VERSION ""

NS_ :

BS_:

BU_: Device Host

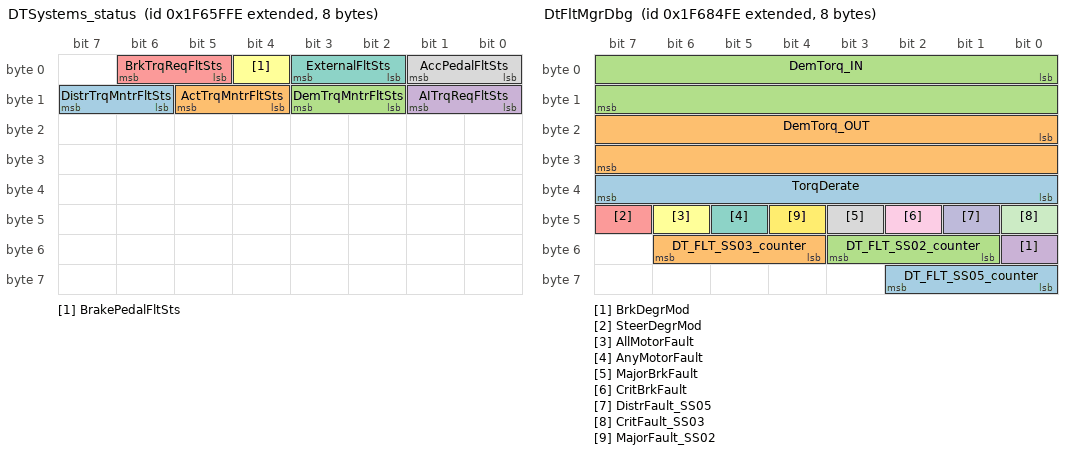
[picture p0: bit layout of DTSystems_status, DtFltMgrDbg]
BO_ 2180407294 DTSystems_status: 8 Vector__XXX
 SG_ DistrTrqMntrFltSts : 14|2@1+ (1,0) [0|3] "" Vector__XXX
 SG_ ActTrqMntrFltSts : 12|2@1+ (1,0) [0|3] "" Vector__XXX
 SG_ DemTrqMntrFltSts : 10|2@1+ (1,0) [0|3] "" Vector__XXX
 SG_ AITrqReqFltSts : 8|2@1+ (1,0) [0|3] "" Vector__XXX
 SG_ BrkTrqReqFltSts : 5|2@1+ (1,0) [0|3] "" Vector__XXX
 SG_ BrakePedalFltSts : 4|1@1+ (1,0) [0|1] "" Vector__XXX
 SG_ ExternalFltSts : 2|2@1+ (1,0) [0|3] "" Vector__XXX
 SG_ AccPedalFltSts : 0|2@1+ (1,0) [0|3] "" Vector__XXX

BO_ 2180416766 DtFltMgrDbg: 8 Vector__XXX
 SG_ DT_FLT_SS05_counter : 56|3@1+ (1,0) [0|7] "" Vector__XXX
 SG_ DT_FLT_SS03_counter : 52|3@1+ (1,0) [0|7] "" Vector__XXX
 SG_ DT_FLT_SS02_counter : 49|3@1+ (1,0) [0|7] "" Vector__XXX
 SG_ BrkDegrMod : 48|1@1+ (1,0) [0|1] "" Vector__XXX
 SG_ SteerDegrMod : 47|1@1+ (1,0) [0|1] "" Vector__XXX
 SG_ AllMotorFault : 46|1@1+ (1,0) [0|1] "" Vector__XXX
 SG_ AnyMotorFault : 45|1@1+ (1,0) [0|1] "" Vector__XXX
 SG_ MajorBrkFault : 43|1@1+ (1,0) [0|1] "" Vector__XXX
 SG_ CritBrkFault : 42|1@1+ (1,0) [0|1] "" Vector__XXX
 SG_ DistrFault_SS05 : 41|1@1+ (1,0) [0|1] "" Vector__XXX
 SG_ CritFault_SS03 : 40|1@1+ (1,0) [0|1] "" Vector__XXX
 SG_ MajorFault_SS02 : 44|1@1+ (1,0) [0|1] "" Vector__XXX
 SG_ TorqDerate : 32|8@1+ (0.004,0) [0|1.02] "" Vector__XXX
 SG_ DemTorq_OUT : 16|16@1+ (1,-32768) [-32768|32767] "" Vector__XXX
 SG_ DemTorq_IN : 0|16@1+ (1,-32768) [-32768|32767] "" Vector__XXX

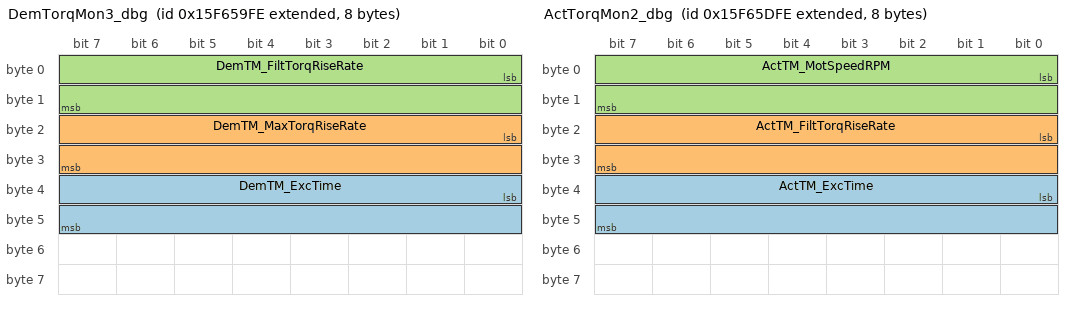
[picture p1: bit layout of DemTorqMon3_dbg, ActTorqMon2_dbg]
BO_ 2515950078 DemTorqMon3_dbg: 8 Vector__XXX
 SG_ DemTM_ExcTime : 32|16@1+ (1,0) [0|65535] "" Vector__XXX
 SG_ DemTM_MaxTorqRiseRate : 16|16@1+ (1,-32267) [-32267|33268] "" Vector__XXX
 SG_ DemTM_FiltTorqRiseRate : 0|16@1+ (1,-32267) [-32267|33268] "" Vector__XXX

BO_ 2515950334 DemTorqMon2_dbg: 8 Vector__XXX
 SG_ DemTM_UpperTorqLim_tab : 16|16@1+ (1,-32267) [-32267|33268] "" Vector__XXX
 SG_ DemTM_LowerTorqLim_tab : 0|16@1+ (1,-32267) [-32267|33268] "" Vector__XXX

BO_ 2515951102 ActTorqMon2_dbg: 8 Vector__XXX
 SG_ ActTM_ExcTime : 32|16@1+ (1,0) [0|65535] "" Vector__XXX
 SG_ ActTM_FiltTorqRiseRate : 16|16@1+ (1,-32267) [-32267|33268] "" Vector__XXX
 SG_ ActTM_MotSpeedRPM : 0|16@1+ (1,-32267) [-32267|33268] "" Vector__XXX

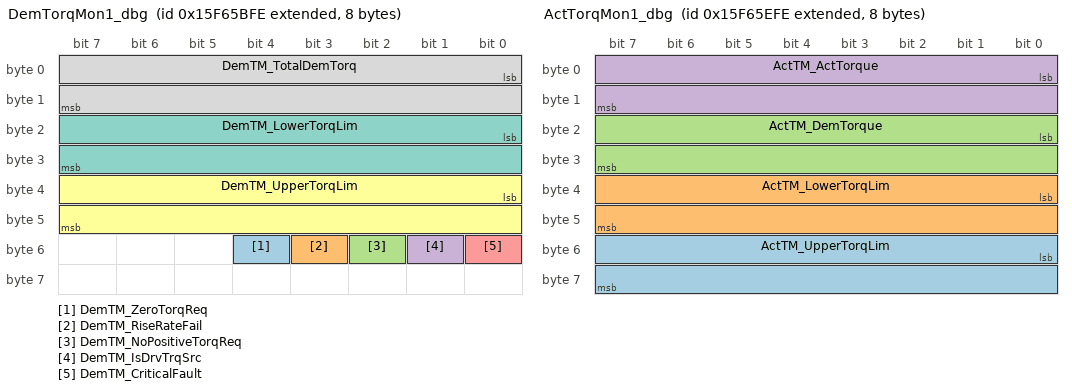
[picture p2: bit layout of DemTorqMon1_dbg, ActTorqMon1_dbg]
BO_ 2515950590 DemTorqMon1_dbg: 8 Vector__XXX
 SG_ DemTM_ZeroTorqReq : 52|1@1+ (1,0) [0|1] "" Vector__XXX
 SG_ DemTM_RiseRateFail : 51|1@1+ (1,0) [0|1] "" Vector__XXX
 SG_ DemTM_NoPositiveTorqReq : 50|1@1+ (1,0) [0|1] "" Vector__XXX
 SG_ DemTM_IsDrvTrqSrc : 49|1@1+ (1,0) [0|1] "" Vector__XXX
 SG_ DemTM_CriticalFault : 48|1@1+ (1,0) [0|1] "" Vector__XXX
 SG_ DemTM_UpperTorqLim : 32|16@1+ (1,-32267) [-32267|33268] "" Vector__XXX
 SG_ DemTM_LowerTorqLim : 16|16@1+ (1,-32267) [-32267|33268] "" Vector__XXX
 SG_ DemTM_TotalDemTorq : 0|16@1+ (1,-32267) [-32267|33268] "" Vector__XXX

BO_ 2515951358 ActTorqMon1_dbg: 8 Vector__XXX
 SG_ ActTM_UpperTorqLim : 48|16@1+ (1,-32267) [-32267|33268] "" Vector__XXX
 SG_ ActTM_LowerTorqLim : 32|16@1+ (1,-32267) [-32267|33268] "" Vector__XXX
 SG_ ActTM_DemTorque : 16|16@1+ (1,-32267) [-32267|33268] "" Vector__XXX
 SG_ ActTM_ActTorque : 0|16@1+ (1,-32267) [-32267|33268] "" Vector__XXX

BO_ 2515950846 BrkTorqMon_dbg: 8 Vector__XXX
 SG_ BrkTM_BrkTorqFault0 : 16|1@1+ (1,0) [0|1] "" Vector__XXX
 SG_ BrkTM_EBSTorqDem : 0|16@1+ (1,-32267) [-32267|33268] "" Vector__XXX

CM_ "Arrival Bus Drivetrain System Database";
CM_ BO_ 2180416766 "Drivetrain Fault Manager Debug";
BA_DEF_  "BusType" STRING ;
BA_DEF_  "DBName" STRING ;
BA_DEF_  "DatabaseVersion" STRING ;
BA_DEF_ BO_  "GenMsgCycleTime" INT 0 3600000;
BA_DEF_ BO_  "Producer" STRING ;
BA_DEF_ BO_  "GenMsgDelayTime" INT 0 1000;
BA_DEF_ BO_  "GenMsgILSupport" ENUM  "No","Yes";
BA_DEF_ BO_  "GenMsgRequestable" INT 0 1;
BA_DEF_ BO_  "GenMsgSendType" ENUM  "cyclic","NotUsed","NotUsed","NotUsed","NotUsed","NotUsed","NotUsed","IfActive","noMsgSendType";
BA_DEF_ SG_  "GenSigEVName" STRING ;
BA_DEF_ SG_  "GenSigILSupport" ENUM  "No","Yes";
BA_DEF_ SG_  "GenSigSendType" ENUM  "Cyclic","OnWrite","OnWriteWithRepetition","OnChange","OnChangeWithRepetition","IfActive","IfActiveWithRepetition","NoSigSendType";
BA_DEF_ SG_  "GenSigStartValue" INT 0 2147483647;
BA_DEF_ BU_  "NmStationAddress" INT 0 255;
BA_DEF_  "ProtocolType" STRING ;
BA_DEF_  "SAE_J1939_21_SpecVersion" STRING ;
BA_DEF_  "SAE_J1939_71_SpecVersion" STRING ;
BA_DEF_  "SAE_J1939_73_SpecVersion" STRING ;
BA_DEF_  "SAE_J1939_75_SpecVersion" STRING ;
BA_DEF_  "SAE_J1939_81_SpecVersion" STRING ;
BA_DEF_  "SAE_J1939_DA_SpecVersion" STRING ;
BA_DEF_ BO_  "SendOnChange" ENUM  "No","Yes";
BA_DEF_ SG_  "SigType" ENUM  "Default","Range","RangeSigned","ASCII","Discrete","Control","ReferencePGN","DTC","StringDelimiter","StringLength","StringLengthControl","MessageCounter","MessageChecksum";
BA_DEF_ BO_  "VFrameFormat" ENUM  "StandardCAN","ExtendedCAN","reserved","J1939PG","reserved","reserved","reserved","reserved","reserved","reserved","reserved","reserved","reserved","reserved","StandardCAN_FD","ExtendedCAN_FD";
BA_DEF_DEF_  "BusType" "";
BA_DEF_DEF_ "Producer" "DTS" ;
BA_DEF_DEF_  "DBName" "";
BA_DEF_DEF_  "DatabaseVersion" "";
BA_DEF_DEF_  "GenMsgCycleTime" 0;
BA_DEF_DEF_  "GenMsgDelayTime" 0;
BA_DEF_DEF_  "GenMsgILSupport" "Yes";
BA_DEF_DEF_  "GenMsgRequestable" 1;
BA_DEF_DEF_  "GenMsgSendType" "noMsgSendType";
BA_DEF_DEF_  "GenSigEVName" "Env@Nodename_@Signame";
BA_DEF_DEF_  "GenSigILSupport" "Yes";
BA_DEF_DEF_  "GenSigSendType" "NoSigSendType";
BA_DEF_DEF_  "GenSigStartValue" 0;
BA_DEF_DEF_  "NmStationAddress" 254;
BA_DEF_DEF_  "ProtocolType" "";
BA_DEF_DEF_  "SAE_J1939_21_SpecVersion" "";
BA_DEF_DEF_  "SAE_J1939_71_SpecVersion" "";
BA_DEF_DEF_  "SAE_J1939_73_SpecVersion" "";
BA_DEF_DEF_  "SAE_J1939_75_SpecVersion" "";
BA_DEF_DEF_  "SAE_J1939_81_SpecVersion" "";
BA_DEF_DEF_  "SAE_J1939_DA_SpecVersion" "";
BA_DEF_DEF_  "SendOnChange" "No";
BA_DEF_DEF_  "SigType" "Default";
BA_DEF_DEF_  "VFrameFormat" "J1939PG";
BA_ "SAE_J1939_DA_SpecVersion" "2015-01";
BA_ "SAE_J1939_81_SpecVersion" "2012-05";
BA_ "SAE_J1939_75_SpecVersion" "2012-05";
BA_ "SAE_J1939_73_SpecVersion" "2012-10";
BA_ "SAE_J1939_71_SpecVersion" "2012-10";
BA_ "SAE_J1939_21_SpecVersion" "2006-10";
BA_ "ProtocolType" "J1939";
BA_ "DatabaseVersion" "1.0";
BA_ "BusType" "CAN";
BA_ "DBName" "DrivetrainSystem";
BA_ "GenMsgCycleTime" BO_ 2180407294 1000;
BA_ "GenMsgDelayTime" BO_ 2180407294 100;
BA_ "GenMsgSendType" BO_ 2180407294 0;
BA_ "SendOnChange" BO_ 2180407294 1;
BA_ "SendOnChange" BO_ 2180416766 1;
BA_ "GenMsgDelayTime" BO_ 2180416766 100;
BA_ "GenMsgCycleTime" BO_ 2180416766 1000;
BA_ "GenMsgSendType" BO_ 2180416766 0;
BA_ "GenMsgCycleTime" BO_ 2515950078 100;
BA_ "GenMsgSendType" BO_ 2515950078 0;
BA_ "GenMsgCycleTime" BO_ 2515950334 100;
BA_ "GenMsgSendType" BO_ 2515950334 0;
BA_ "GenMsgCycleTime" BO_ 2515951102 100;
BA_ "GenMsgSendType" BO_ 2515951102 0;
BA_ "GenMsgSendType" BO_ 2515950590 0;
BA_ "GenMsgCycleTime" BO_ 2515950590 100;
BA_ "GenMsgSendType" BO_ 2515951358 0;
BA_ "GenMsgCycleTime" BO_ 2515951358 100;
BA_ "GenMsgSendType" BO_ 2515950846 0;
BA_ "GenMsgCycleTime" BO_ 2515950846 100;
BA_ "GenSigStartValue" SG_ 2180416766 DemTorq_OUT 32768;
BA_ "GenSigStartValue" SG_ 2180416766 DemTorq_IN 32768;
BA_ "GenSigStartValue" SG_ 2515950078 DemTM_MaxTorqRiseRate 32267;
BA_ "GenSigStartValue" SG_ 2515950078 DemTM_FiltTorqRiseRate 32267;
BA_ "GenSigStartValue" SG_ 2515950334 DemTM_UpperTorqLim_tab 32267;
BA_ "GenSigStartValue" SG_ 2515950334 DemTM_LowerTorqLim_tab 32267;
BA_ "GenSigStartValue" SG_ 2515951102 ActTM_FiltTorqRiseRate 32267;
BA_ "GenSigStartValue" SG_ 2515951102 ActTM_MotSpeedRPM 32267;
BA_ "GenSigStartValue" SG_ 2515950590 DemTM_UpperTorqLim 32267;
BA_ "GenSigStartValue" SG_ 2515950590 DemTM_LowerTorqLim 32267;
BA_ "GenSigStartValue" SG_ 2515950590 DemTM_TotalDemTorq 32267;
BA_ "GenSigStartValue" SG_ 2515951358 ActTM_UpperTorqLim 32267;
BA_ "GenSigStartValue" SG_ 2515951358 ActTM_LowerTorqLim 32267;
BA_ "GenSigStartValue" SG_ 2515951358 ActTM_DemTorque 32267;
BA_ "GenSigStartValue" SG_ 2515951358 ActTM_ActTorque 32267;
BA_ "GenSigStartValue" SG_ 2515950846 BrkTM_EBSTorqDem 32267;
VAL_ 2180407294 DistrTrqMntrFltSts 3 "DistrTrqNotAvailable" 2 "CriticalDistrTrqMntrFault" 1 "MajorDistrTrqMntrFault" 0 "NoDistrTrqMntrFault" ;
VAL_ 2180407294 ActTrqMntrFltSts 3 "ActTrqNotAvailable" 2 "CriticalActTrqMntrFault" 1 "MajorActTrqMntrFault" 0 "NoActTrqMntrFault" ;
VAL_ 2180407294 DemTrqMntrFltSts 3 "DemTrqNotAvailable" 2 "CriticalDemTrqMntrFault" 1 "MajorDemTrqMntrFault" 0 "NoDemTrqMntrFault" ;
VAL_ 2180407294 AITrqReqFltSts 3 "AITrqNotAvailable" 2 "CriticalAITrqReqFault" 1 "MajorAITrqReqFault" 0 "NoAITrqReqFault" ;
VAL_ 2180407294 BrkTrqReqFltSts 3 "BrkTrqNotAvailable" 2 "CriticalBrkTrqReqFault" 1 "MajorBrkTrqReqFault" 0 "NoBrkTrqReqFault" ;
VAL_ 2180407294 BrakePedalFltSts 1 "BrakePedalFault" 0 "NoBrakePedalFault" ;
VAL_ 2180407294 ExternalFltSts 3 "CriticalExternalFault" 2 "MajorExternalFault" 1 "MinorExternalFault" 0 "NoExternalFault" ;
VAL_ 2180407294 AccPedalFltSts 3 "AccNotAvailable" 2 "CriticalAccPedalFault" 1 "MajorAccPedalFault" 0 "NoAccPedalFault" ;
